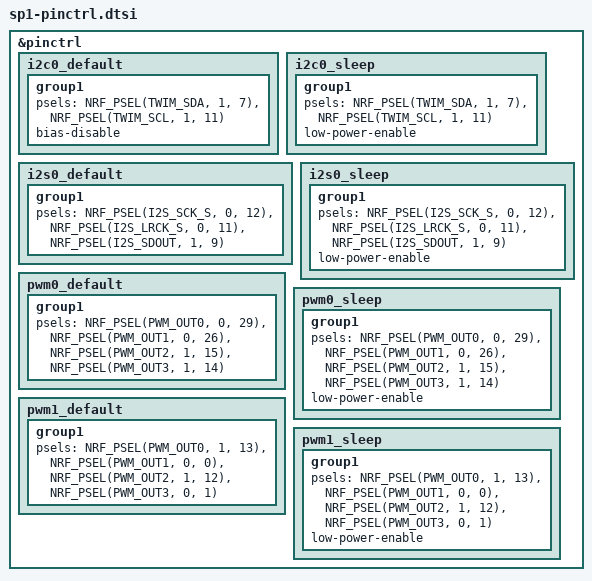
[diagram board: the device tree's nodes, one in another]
/*
 * SPDX-License-Identifier: MIT
 *
 * Pins from timknapen/SP-1-dev src/stemplayer_pins.h.
 */

&pinctrl {
	i2c0_default: i2c0_default {
		group1 {
			psels = <NRF_PSEL(TWIM_SDA, 1, 7)>,
				<NRF_PSEL(TWIM_SCL, 1, 11)>;
			/* 4.7 k pull-ups on the PCB */
			bias-disable;
		};
	};

	i2c0_sleep: i2c0_sleep {
		group1 {
			psels = <NRF_PSEL(TWIM_SDA, 1, 7)>,
				<NRF_PSEL(TWIM_SCL, 1, 11)>;
			low-power-enable;
		};
	};

	/* The nRF is a clock slave: SCK comes from the 3.072 MHz oscillator,
	 * LRCK from the CS42L42.
	 */
	i2s0_default: i2s0_default {
		group1 {
			psels = <NRF_PSEL(I2S_SCK_S, 0, 12)>,
				<NRF_PSEL(I2S_LRCK_S, 0, 11)>,
				<NRF_PSEL(I2S_SDOUT, 1, 9)>;
		};
	};

	i2s0_sleep: i2s0_sleep {
		group1 {
			psels = <NRF_PSEL(I2S_SCK_S, 0, 12)>,
				<NRF_PSEL(I2S_LRCK_S, 0, 11)>,
				<NRF_PSEL(I2S_SDOUT, 1, 9)>;
			low-power-enable;
		};
	};

	/* Track LEDs 1-4 */
	pwm0_default: pwm0_default {
		group1 {
			psels = <NRF_PSEL(PWM_OUT0, 0, 29)>,
				<NRF_PSEL(PWM_OUT1, 0, 26)>,
				<NRF_PSEL(PWM_OUT2, 1, 15)>,
				<NRF_PSEL(PWM_OUT3, 1, 14)>;
		};
	};

	pwm0_sleep: pwm0_sleep {
		group1 {
			psels = <NRF_PSEL(PWM_OUT0, 0, 29)>,
				<NRF_PSEL(PWM_OUT1, 0, 26)>,
				<NRF_PSEL(PWM_OUT2, 1, 15)>,
				<NRF_PSEL(PWM_OUT3, 1, 14)>;
			low-power-enable;
		};
	};

	/* Playback LEDs 1-4 (between PLAY and FUNCTION) */
	pwm1_default: pwm1_default {
		group1 {
			psels = <NRF_PSEL(PWM_OUT0, 1, 13)>,
				<NRF_PSEL(PWM_OUT1, 0, 0)>,
				<NRF_PSEL(PWM_OUT2, 1, 12)>,
				<NRF_PSEL(PWM_OUT3, 0, 1)>;
		};
	};

	pwm1_sleep: pwm1_sleep {
		group1 {
			psels = <NRF_PSEL(PWM_OUT0, 1, 13)>,
				<NRF_PSEL(PWM_OUT1, 0, 0)>,
				<NRF_PSEL(PWM_OUT2, 1, 12)>,
				<NRF_PSEL(PWM_OUT3, 0, 1)>;
			low-power-enable;
		};
	};
};
